AUTOSAR XML (schema 3-2-1)
package /SeatHeater/SeatHeatingController_swc
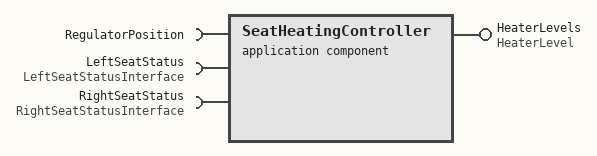
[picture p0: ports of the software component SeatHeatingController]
  application software component type SeatHeatingController
    require port RegulatorPosition: unqueued-provider-com-spec{data-element=Position, alive-timeout=60.0}, provided-interface=RegulatorPosition
    provide port HeaterLevels: provided-com-specs=[{data-element=LeftHeatLevel, alive-timeout=60.0}, {data-element=RightHeatLevel, alive-timeout=60.0}], provided-interface=HeaterLevel
    require port LeftSeatStatus: unqueued-provider-com-spec{data-element=PassengerOnLeftSeat, alive-timeout=60.0}, provided-interface=LeftSeatStatusInterface
    require port RightSeatStatus: unqueued-provider-com-spec{data-element=PassengerOnRightSeat, alive-timeout=60.0}, provided-interface=RightSeatStatusInterface
  internal behavior SeatHeatingControllerBehavior: compontent=SeatHeatingController
    timing event HeatingUpdateEvent: start-on-event=UpdateHeating, period=0.0
    runnable UpdateHeating: can-be-invoked-concurrently=true
      5 x data read access:
        RegulatorPositionAccess: data-element=RegulatorPosition.Position
        HeaterRightLevelAccess: data-element=RightSeatStatus.PassengerOnRightSeat
        HeaterLeftLevelAccess: data-element=HeaterLevels.RightHeatLevel
        RightSeatStatusAccess: data-element=RightSeatStatus.PassengerOnRightSeat
        LeftSeatStatusAccess: data-element=LeftSeatStatus.PassengerOnLeftSeat
  swc implementation SeatHeatingControllerImplementation: behavior=SeatHeatingControllerBehavior
